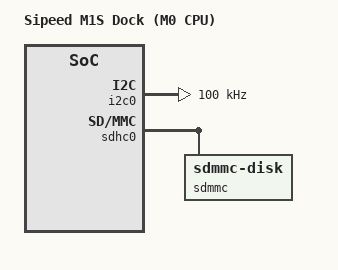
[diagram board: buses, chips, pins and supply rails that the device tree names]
/*
 * Copyright The Zephyr Project Contributors
 *
 * SPDX-License-Identifier: Apache-2.0
 */

/dts-v1/;

#include "m1s_m0.dtsi"
#include "m1s_dock_common.dtsi"

/ {
	model = "Sipeed M1S Dock (M0 CPU)";

	aliases {
		pwm-led0 = &user_pwm_led0;
		sdhc0 = &sdhc0;
	};

	pwmleds: pwmleds {
		compatible = "pwm-leds";
		status = "disabled";

		user_pwm_led0: pwm_led_0 {
			pwms = <&pwm0 0 PWM_MSEC(20) PWM_POLARITY_NORMAL>;
			label = "User PWM LED";
		};
	};
};

&i2c0 {
	status = "okay";
	pinctrl-0 = <&i2c0_default>;
	pinctrl-names = "default";
	clock-frequency = <I2C_BITRATE_STANDARD>;
};

&sdhc0 {
	pinctrl-0 = <&sdhc0_default>;
	pinctrl-names = "default";
	status = "okay";

	sdmmc {
		compatible = "zephyr,sdmmc-disk";
		disk-name = "SD";
		status = "okay";
	};
};
